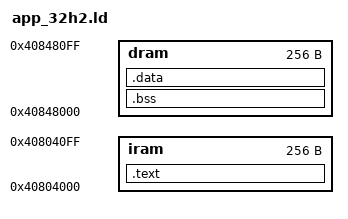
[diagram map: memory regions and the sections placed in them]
/*
 * SPDX-FileCopyrightText: 2023 Espressif Systems (Shanghai) CO LTD
 *
 * SPDX-License-Identifier: GPL-2.0-or-later
 */

MEMORY {
  iram : org = 0x40804000, len = 0x100
  dram : org = 0x40848000, len = 0x100
}

ENTRY(ram_main)

SECTIONS {
  .text : ALIGN(4) {
    *(.literal)
    *(.text .text.*)
  } > iram

  .bss : ALIGN(4) {
    _bss_start = ABSOLUTE(.);
    *(.bss)
    _bss_end = ABSOLUTE(.);
  } > dram

  .data : ALIGN(4) {
    *(.data)
    *(.rodata .rodata.*)
  } > dram
}

INCLUDE "../../../../flasher_stub/ld/rom_32h2.ld"
